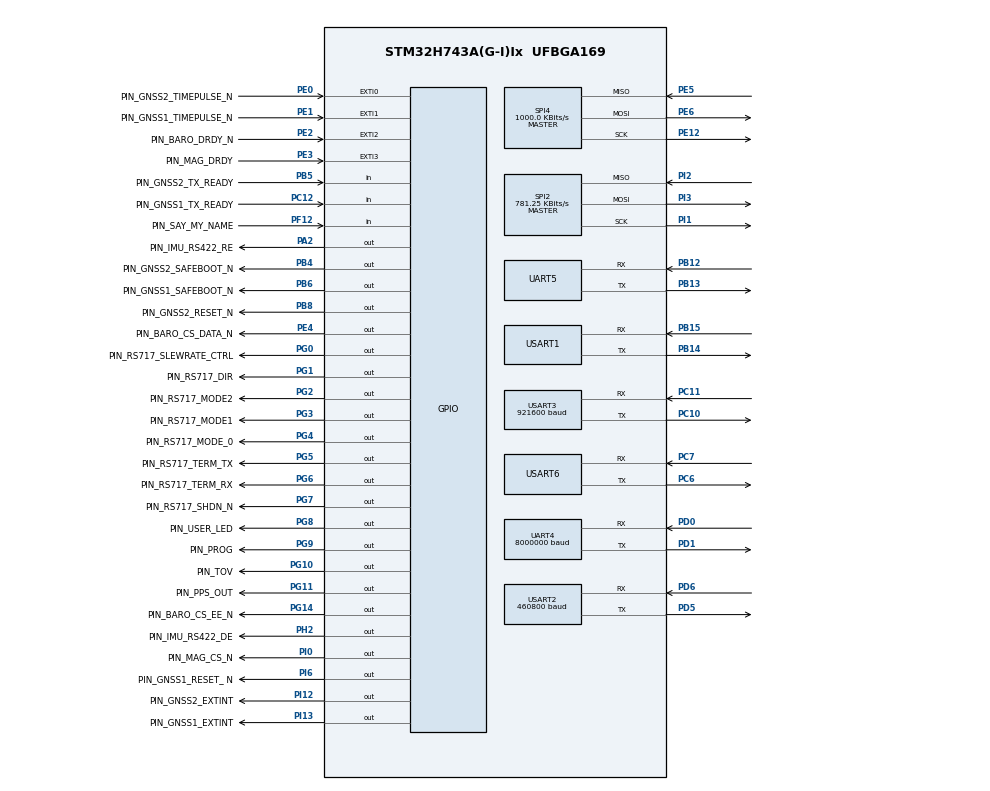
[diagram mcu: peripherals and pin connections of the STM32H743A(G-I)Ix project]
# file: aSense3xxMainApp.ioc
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CORTEX_M7.AccessPermission_Spec=MPU_REGION_FULL_ACCESS
CORTEX_M7.BaseAddress_Spec=0x24078000
CORTEX_M7.CPU_DCache=Enabled
CORTEX_M7.CPU_ICache=Enabled
CORTEX_M7.DisableExec_Spec=MPU_INSTRUCTION_ACCESS_ENABLE
CORTEX_M7.IsBufferable_Spec=MPU_ACCESS_BUFFERABLE
CORTEX_M7.IsShareable_Spec=MPU_ACCESS_SHAREABLE
CORTEX_M7.Size_Spec=MPU_REGION_SIZE_32KB
CORTEX_M7.SubRegionDisable_Spec=0x0
CORTEX_M7.default_mode_Activation=1
Dma.Request0=SPI2_RX
Dma.Request1=SPI2_TX
Dma.Request10=USART1_RX
Dma.Request11=USART1_TX
Dma.Request12=UART5_RX
Dma.Request13=UART5_TX
Dma.Request14=USART6_RX
Dma.Request15=USART6_TX
Dma.Request2=SPI4_RX
Dma.Request3=SPI4_TX
Dma.Request4=UART4_RX
Dma.Request5=UART4_TX
Dma.Request6=USART2_TX
Dma.Request7=USART2_RX
Dma.Request8=USART3_RX
Dma.Request9=USART3_TX
Dma.SPI2_RX.0.Direction=DMA_PERIPH_TO_MEMORY
Dma.SPI2_RX.0.EventEnable=DISABLE
Dma.SPI2_RX.0.FIFOMode=DMA_FIFOMODE_DISABLE
Dma.SPI2_RX.0.Instance=DMA1_Stream0
Dma.SPI2_RX.0.MemDataAlignment=DMA_MDATAALIGN_BYTE
Dma.SPI2_RX.0.MemInc=DMA_MINC_ENABLE
Dma.SPI2_RX.0.Mode=DMA_NORMAL
Dma.SPI2_RX.0.PeriphDataAlignment=DMA_PDATAALIGN_BYTE
Dma.SPI2_RX.0.PeriphInc=DMA_PINC_DISABLE
Dma.SPI2_RX.0.Polarity=HAL_DMAMUX_REQ_GEN_RISING
Dma.SPI2_RX.0.Priority=DMA_PRIORITY_LOW
Dma.SPI2_RX.0.RequestNumber=1
Dma.SPI2_RX.0.SignalID=NONE
Dma.SPI2_RX.0.SyncEnable=DISABLE
Dma.SPI2_RX.0.SyncPolarity=HAL_DMAMUX_SYNC_NO_EVENT
Dma.SPI2_RX.0.SyncRequestNumber=1
Dma.SPI2_RX.0.SyncSignalID=NONE
Dma.SPI2_TX.1.Direction=DMA_MEMORY_TO_PERIPH
Dma.SPI2_TX.1.EventEnable=DISABLE
Dma.SPI2_TX.1.FIFOMode=DMA_FIFOMODE_DISABLE
Dma.SPI2_TX.1.Instance=DMA1_Stream1
Dma.SPI2_TX.1.MemDataAlignment=DMA_MDATAALIGN_BYTE
Dma.SPI2_TX.1.MemInc=DMA_MINC_ENABLE
Dma.SPI2_TX.1.Mode=DMA_NORMAL
Dma.SPI2_TX.1.PeriphDataAlignment=DMA_PDATAALIGN_BYTE
Dma.SPI2_TX.1.PeriphInc=DMA_PINC_DISABLE
Dma.SPI2_TX.1.Polarity=HAL_DMAMUX_REQ_GEN_RISING
Dma.SPI2_TX.1.Priority=DMA_PRIORITY_LOW
Dma.SPI2_TX.1.RequestNumber=1
Dma.SPI2_TX.1.SignalID=NONE
Dma.SPI2_TX.1.SyncEnable=DISABLE
Dma.SPI2_TX.1.SyncPolarity=HAL_DMAMUX_SYNC_NO_EVENT
Dma.SPI2_TX.1.SyncRequestNumber=1
Dma.SPI2_TX.1.SyncSignalID=NONE
Dma.SPI4_RX.2.Direction=DMA_PERIPH_TO_MEMORY
Dma.SPI4_RX.2.EventEnable=DISABLE
Dma.SPI4_RX.2.FIFOMode=DMA_FIFOMODE_DISABLE
Dma.SPI4_RX.2.Instance=DMA1_Stream2
Dma.SPI4_RX.2.MemDataAlignment=DMA_MDATAALIGN_BYTE
Dma.SPI4_RX.2.MemInc=DMA_MINC_ENABLE
Dma.SPI4_RX.2.Mode=DMA_NORMAL
Dma.SPI4_RX.2.PeriphDataAlignment=DMA_PDATAALIGN_BYTE
Dma.SPI4_RX.2.PeriphInc=DMA_PINC_DISABLE
Dma.SPI4_RX.2.Polarity=HAL_DMAMUX_REQ_GEN_RISING
Dma.SPI4_RX.2.Priority=DMA_PRIORITY_LOW
Dma.SPI4_RX.2.RequestNumber=1
Dma.SPI4_RX.2.SignalID=NONE
Dma.SPI4_RX.2.SyncEnable=DISABLE
Dma.SPI4_RX.2.SyncPolarity=HAL_DMAMUX_SYNC_NO_EVENT
Dma.SPI4_RX.2.SyncRequestNumber=1
Dma.SPI4_RX.2.SyncSignalID=NONE
Dma.SPI4_TX.3.Direction=DMA_MEMORY_TO_PERIPH
Dma.SPI4_TX.3.EventEnable=DISABLE
Dma.SPI4_TX.3.FIFOMode=DMA_FIFOMODE_DISABLE
Dma.SPI4_TX.3.Instance=DMA1_Stream3
Dma.SPI4_TX.3.MemDataAlignment=DMA_MDATAALIGN_BYTE
Dma.SPI4_TX.3.MemInc=DMA_MINC_ENABLE
Dma.SPI4_TX.3.Mode=DMA_NORMAL
Dma.SPI4_TX.3.PeriphDataAlignment=DMA_PDATAALIGN_BYTE
Dma.SPI4_TX.3.PeriphInc=DMA_PINC_DISABLE
Dma.SPI4_TX.3.Polarity=HAL_DMAMUX_REQ_GEN_RISING
Dma.SPI4_TX.3.Priority=DMA_PRIORITY_LOW
Dma.SPI4_TX.3.RequestNumber=1
Dma.SPI4_TX.3.SignalID=NONE
Dma.SPI4_TX.3.SyncEnable=DISABLE
Dma.SPI4_TX.3.SyncPolarity=HAL_DMAMUX_SYNC_NO_EVENT
Dma.SPI4_TX.3.SyncRequestNumber=1
Dma.SPI4_TX.3.SyncSignalID=NONE
Dma.UART4_RX.4.Direction=DMA_PERIPH_TO_MEMORY
Dma.UART4_RX.4.EventEnable=DISABLE
Dma.UART4_RX.4.FIFOMode=DMA_FIFOMODE_DISABLE
Dma.UART4_RX.4.Instance=DMA1_Stream4
Dma.UART4_RX.4.MemDataAlignment=DMA_MDATAALIGN_BYTE
Dma.UART4_RX.4.MemInc=DMA_MINC_ENABLE
Dma.UART4_RX.4.Mode=DMA_CIRCULAR
Dma.UART4_RX.4.PeriphDataAlignment=DMA_PDATAALIGN_BYTE
Dma.UART4_RX.4.PeriphInc=DMA_PINC_DISABLE
Dma.UART4_RX.4.Polarity=HAL_DMAMUX_REQ_GEN_RISING
Dma.UART4_RX.4.Priority=DMA_PRIORITY_LOW
Dma.UART4_RX.4.RequestNumber=1
Dma.UART4_RX.4.SignalID=NONE
Dma.UART4_RX.4.SyncEnable=DISABLE
Dma.UART4_RX.4.SyncPolarity=HAL_DMAMUX_SYNC_NO_EVENT
Dma.UART4_RX.4.SyncRequestNumber=1
Dma.UART4_RX.4.SyncSignalID=NONE
Dma.UART4_TX.5.Direction=DMA_MEMORY_TO_PERIPH
Dma.UART4_TX.5.EventEnable=DISABLE
Dma.UART4_TX.5.FIFOMode=DMA_FIFOMODE_DISABLE
Dma.UART4_TX.5.Instance=DMA1_Stream5
Dma.UART4_TX.5.MemDataAlignment=DMA_MDATAALIGN_BYTE
Dma.UART4_TX.5.MemInc=DMA_MINC_ENABLE
Dma.UART4_TX.5.Mode=DMA_NORMAL
Dma.UART4_TX.5.PeriphDataAlignment=DMA_PDATAALIGN_BYTE
Dma.UART4_TX.5.PeriphInc=DMA_PINC_DISABLE
Dma.UART4_TX.5.Polarity=HAL_DMAMUX_REQ_GEN_RISING
Dma.UART4_TX.5.Priority=DMA_PRIORITY_LOW
Dma.UART4_TX.5.RequestNumber=1
Dma.UART4_TX.5.SignalID=NONE
Dma.UART4_TX.5.SyncEnable=DISABLE
Dma.UART4_TX.5.SyncPolarity=HAL_DMAMUX_SYNC_NO_EVENT
Dma.UART4_TX.5.SyncRequestNumber=1
Dma.UART4_TX.5.SyncSignalID=NONE
Dma.UART5_RX.12.Direction=DMA_PERIPH_TO_MEMORY
Dma.UART5_RX.12.EventEnable=DISABLE
Dma.UART5_RX.12.FIFOMode=DMA_FIFOMODE_DISABLE
Dma.UART5_RX.12.Instance=DMA2_Stream0
Dma.UART5_RX.12.MemDataAlignment=DMA_MDATAALIGN_BYTE
Dma.UART5_RX.12.MemInc=DMA_MINC_ENABLE
Dma.UART5_RX.12.Mode=DMA_CIRCULAR
Dma.UART5_RX.12.PeriphDataAlignment=DMA_PDATAALIGN_BYTE
Dma.UART5_RX.12.PeriphInc=DMA_PINC_DISABLE
Dma.UART5_RX.12.Polarity=HAL_DMAMUX_REQ_GEN_RISING
Dma.UART5_RX.12.Priority=DMA_PRIORITY_LOW
Dma.UART5_RX.12.RequestNumber=1
Dma.UART5_RX.12.SignalID=NONE
Dma.UART5_RX.12.SyncEnable=DISABLE
Dma.UART5_RX.12.SyncPolarity=HAL_DMAMUX_SYNC_NO_EVENT
Dma.UART5_RX.12.SyncRequestNumber=1
Dma.UART5_RX.12.SyncSignalID=NONE
Dma.UART5_TX.13.Direction=DMA_MEMORY_TO_PERIPH
Dma.UART5_TX.13.EventEnable=DISABLE
Dma.UART5_TX.13.FIFOMode=DMA_FIFOMODE_DISABLE
Dma.UART5_TX.13.Instance=DMA2_Stream1
Dma.UART5_TX.13.MemDataAlignment=DMA_MDATAALIGN_BYTE
Dma.UART5_TX.13.MemInc=DMA_MINC_ENABLE
Dma.UART5_TX.13.Mode=DMA_NORMAL
Dma.UART5_TX.13.PeriphDataAlignment=DMA_PDATAALIGN_BYTE
Dma.UART5_TX.13.PeriphInc=DMA_PINC_DISABLE
Dma.UART5_TX.13.Polarity=HAL_DMAMUX_REQ_GEN_RISING
Dma.UART5_TX.13.Priority=DMA_PRIORITY_LOW
Dma.UART5_TX.13.RequestNumber=1
Dma.UART5_TX.13.SignalID=NONE
Dma.UART5_TX.13.SyncEnable=DISABLE
Dma.UART5_TX.13.SyncPolarity=HAL_DMAMUX_SYNC_NO_EVENT
Dma.UART5_TX.13.SyncRequestNumber=1
Dma.UART5_TX.13.SyncSignalID=NONE
Dma.USART1_RX.10.Direction=DMA_PERIPH_TO_MEMORY
Dma.USART1_RX.10.EventEnable=DISABLE
Dma.USART1_RX.10.FIFOMode=DMA_FIFOMODE_DISABLE
Dma.USART1_RX.10.Instance=DMA1_Stream6
Dma.USART1_RX.10.MemDataAlignment=DMA_MDATAALIGN_BYTE
Dma.USART1_RX.10.MemInc=DMA_MINC_ENABLE
Dma.USART1_RX.10.Mode=DMA_CIRCULAR
Dma.USART1_RX.10.PeriphDataAlignment=DMA_PDATAALIGN_BYTE
Dma.USART1_RX.10.PeriphInc=DMA_PINC_DISABLE
Dma.USART1_RX.10.Polarity=HAL_DMAMUX_REQ_GEN_RISING
Dma.USART1_RX.10.Priority=DMA_PRIORITY_LOW
Dma.USART1_RX.10.RequestNumber=1
Dma.USART1_RX.10.SignalID=NONE
Dma.USART1_RX.10.SyncEnable=DISABLE
Dma.USART1_RX.10.SyncPolarity=HAL_DMAMUX_SYNC_NO_EVENT
Dma.USART1_RX.10.SyncRequestNumber=1
Dma.USART1_RX.10.SyncSignalID=NONE
Dma.USART1_TX.11.Direction=DMA_MEMORY_TO_PERIPH
Dma.USART1_TX.11.EventEnable=DISABLE
Dma.USART1_TX.11.FIFOMode=DMA_FIFOMODE_DISABLE
Dma.USART1_TX.11.Instance=DMA1_Stream7
Dma.USART1_TX.11.MemDataAlignment=DMA_MDATAALIGN_BYTE
Dma.USART1_TX.11.MemInc=DMA_MINC_ENABLE
Dma.USART1_TX.11.Mode=DMA_NORMAL
Dma.USART1_TX.11.PeriphDataAlignment=DMA_PDATAALIGN_BYTE
Dma.USART1_TX.11.PeriphInc=DMA_PINC_DISABLE
Dma.USART1_TX.11.Polarity=HAL_DMAMUX_REQ_GEN_RISING
Dma.USART1_TX.11.Priority=DMA_PRIORITY_LOW
Dma.USART1_TX.11.RequestNumber=1
Dma.USART1_TX.11.SignalID=NONE
Dma.USART1_TX.11.SyncEnable=DISABLE
Dma.USART1_TX.11.SyncPolarity=HAL_DMAMUX_SYNC_NO_EVENT
Dma.USART1_TX.11.SyncRequestNumber=1
Dma.USART1_TX.11.SyncSignalID=NONE
Dma.USART2_RX.7.Direction=DMA_PERIPH_TO_MEMORY
Dma.USART2_RX.7.EventEnable=DISABLE
Dma.USART2_RX.7.FIFOMode=DMA_FIFOMODE_DISABLE
Dma.USART2_RX.7.Instance=DMA2_Stream3
Dma.USART2_RX.7.MemDataAlignment=DMA_MDATAALIGN_BYTE
Dma.USART2_RX.7.MemInc=DMA_MINC_ENABLE
Dma.USART2_RX.7.Mode=DMA_CIRCULAR
Dma.USART2_RX.7.PeriphDataAlignment=DMA_PDATAALIGN_BYTE
Dma.USART2_RX.7.PeriphInc=DMA_PINC_DISABLE
Dma.USART2_RX.7.Polarity=HAL_DMAMUX_REQ_GEN_RISING
Dma.USART2_RX.7.Priority=DMA_PRIORITY_LOW
Dma.USART2_RX.7.RequestNumber=1
Dma.USART2_RX.7.SignalID=NONE
Dma.USART2_RX.7.SyncEnable=DISABLE
Dma.USART2_RX.7.SyncPolarity=HAL_DMAMUX_SYNC_NO_EVENT
Dma.USART2_RX.7.SyncRequestNumber=1
Dma.USART2_RX.7.SyncSignalID=NONE
Dma.USART2_TX.6.Direction=DMA_MEMORY_TO_PERIPH
Dma.USART2_TX.6.EventEnable=DISABLE
Dma.USART2_TX.6.FIFOMode=DMA_FIFOMODE_DISABLE
Dma.USART2_TX.6.Instance=DMA2_Stream2
Dma.USART2_TX.6.MemDataAlignment=DMA_MDATAALIGN_BYTE
Dma.USART2_TX.6.MemInc=DMA_MINC_ENABLE
Dma.USART2_TX.6.Mode=DMA_NORMAL
Dma.USART2_TX.6.PeriphDataAlignment=DMA_PDATAALIGN_BYTE
Dma.USART2_TX.6.PeriphInc=DMA_PINC_DISABLE
Dma.USART2_TX.6.Polarity=HAL_DMAMUX_REQ_GEN_RISING
Dma.USART2_TX.6.Priority=DMA_PRIORITY_LOW
Dma.USART2_TX.6.RequestNumber=1
Dma.USART2_TX.6.SignalID=NONE
Dma.USART2_TX.6.SyncEnable=DISABLE
Dma.USART2_TX.6.SyncPolarity=HAL_DMAMUX_SYNC_NO_EVENT
Dma.USART2_TX.6.SyncRequestNumber=1
Dma.USART2_TX.6.SyncSignalID=NONE
Dma.USART3_RX.8.Direction=DMA_PERIPH_TO_MEMORY
Dma.USART3_RX.8.EventEnable=DISABLE
Dma.USART3_RX.8.FIFOMode=DMA_FIFOMODE_DISABLE
Dma.USART3_RX.8.Instance=DMA2_Stream4
Dma.USART3_RX.8.MemDataAlignment=DMA_MDATAALIGN_BYTE
Dma.USART3_RX.8.MemInc=DMA_MINC_ENABLE
Dma.USART3_RX.8.Mode=DMA_CIRCULAR
Dma.USART3_RX.8.PeriphDataAlignment=DMA_PDATAALIGN_BYTE
Dma.USART3_RX.8.PeriphInc=DMA_PINC_DISABLE
Dma.USART3_RX.8.Polarity=HAL_DMAMUX_REQ_GEN_RISING
Dma.USART3_RX.8.Priority=DMA_PRIORITY_LOW
Dma.USART3_RX.8.RequestNumber=1
Dma.USART3_RX.8.SignalID=NONE
Dma.USART3_RX.8.SyncEnable=DISABLE
Dma.USART3_RX.8.SyncPolarity=HAL_DMAMUX_SYNC_NO_EVENT
Dma.USART3_RX.8.SyncRequestNumber=1
Dma.USART3_RX.8.SyncSignalID=NONE
Dma.USART3_TX.9.Direction=DMA_MEMORY_TO_PERIPH
Dma.USART3_TX.9.EventEnable=DISABLE
Dma.USART3_TX.9.FIFOMode=DMA_FIFOMODE_DISABLE
Dma.USART3_TX.9.Instance=DMA2_Stream5
Dma.USART3_TX.9.MemDataAlignment=DMA_MDATAALIGN_BYTE
Dma.USART3_TX.9.MemInc=DMA_MINC_ENABLE
Dma.USART3_TX.9.Mode=DMA_NORMAL
Dma.USART3_TX.9.PeriphDataAlignment=DMA_PDATAALIGN_BYTE
Dma.USART3_TX.9.PeriphInc=DMA_PINC_DISABLE
Dma.USART3_TX.9.Polarity=HAL_DMAMUX_REQ_GEN_RISING
Dma.USART3_TX.9.Priority=DMA_PRIORITY_LOW
Dma.USART3_TX.9.RequestNumber=1
Dma.USART3_TX.9.SignalID=NONE
Dma.USART3_TX.9.SyncEnable=DISABLE
Dma.USART3_TX.9.SyncPolarity=HAL_DMAMUX_SYNC_NO_EVENT
Dma.USART3_TX.9.SyncRequestNumber=1
Dma.USART3_TX.9.SyncSignalID=NONE
Dma.USART6_RX.14.Direction=DMA_PERIPH_TO_MEMORY
Dma.USART6_RX.14.EventEnable=DISABLE
Dma.USART6_RX.14.FIFOMode=DMA_FIFOMODE_DISABLE
Dma.USART6_RX.14.Instance=DMA2_Stream6
Dma.USART6_RX.14.MemDataAlignment=DMA_MDATAALIGN_BYTE
Dma.USART6_RX.14.MemInc=DMA_MINC_ENABLE
Dma.USART6_RX.14.Mode=DMA_CIRCULAR
Dma.USART6_RX.14.PeriphDataAlignment=DMA_PDATAALIGN_BYTE
Dma.USART6_RX.14.PeriphInc=DMA_PINC_DISABLE
Dma.USART6_RX.14.Polarity=HAL_DMAMUX_REQ_GEN_RISING
Dma.USART6_RX.14.Priority=DMA_PRIORITY_LOW
Dma.USART6_RX.14.RequestNumber=1
Dma.USART6_RX.14.SignalID=NONE
Dma.USART6_RX.14.SyncEnable=DISABLE
Dma.USART6_RX.14.SyncPolarity=HAL_DMAMUX_SYNC_NO_EVENT
Dma.USART6_RX.14.SyncRequestNumber=1
Dma.USART6_RX.14.SyncSignalID=NONE
Dma.USART6_TX.15.Direction=DMA_MEMORY_TO_PERIPH
Dma.USART6_TX.15.EventEnable=DISABLE
Dma.USART6_TX.15.FIFOMode=DMA_FIFOMODE_DISABLE
Dma.USART6_TX.15.Instance=DMA2_Stream7
Dma.USART6_TX.15.MemDataAlignment=DMA_MDATAALIGN_BYTE
Dma.USART6_TX.15.MemInc=DMA_MINC_ENABLE
Dma.USART6_TX.15.Mode=DMA_NORMAL
Dma.USART6_TX.15.PeriphDataAlignment=DMA_PDATAALIGN_BYTE
Dma.USART6_TX.15.PeriphInc=DMA_PINC_DISABLE
Dma.USART6_TX.15.Polarity=HAL_DMAMUX_REQ_GEN_RISING
Dma.USART6_TX.15.Priority=DMA_PRIORITY_LOW
Dma.USART6_TX.15.RequestNumber=1
Dma.USART6_TX.15.SignalID=NONE
Dma.USART6_TX.15.SyncEnable=DISABLE
Dma.USART6_TX.15.SyncPolarity=HAL_DMAMUX_SYNC_NO_EVENT
Dma.USART6_TX.15.SyncRequestNumber=1
Dma.USART6_TX.15.SyncSignalID=NONE
Mcu.Family=STM32H7
Mcu.Name=STM32H743A(G-I)Ix
Mcu.Package=UFBGA169
Mcu.UserConstants=SPI_BARO,$$_SPI4_IP_HANDLE_$$;UART_DELTAIMU,$$_USART2_IP_HANDLE_$$;SPI_MAGNETO,$$_SPI2_IP_HANDLE_$$;UART_EXTERNAL,$$_UART4_IP_HANDLE_$$;UART_RS717,$$_USART3_IP_HANDLE_$$;UART_GNSS1,$$_USART1_IP_HANDLE_$$;UART_GNSS2,$$_UART5_IP_HANDLE_$$
NVIC.DMA1_Stream0_IRQn=true\:4\:0\:true\:false\:true\:false\:false\:true\:true
NVIC.DMA1_Stream1_IRQn=true\:4\:0\:true\:false\:true\:false\:false\:true\:true
NVIC.DMA1_Stream2_IRQn=true\:4\:0\:true\:false\:true\:false\:false\:true\:true
NVIC.DMA1_Stream3_IRQn=true\:4\:0\:true\:false\:true\:false\:false\:true\:true
NVIC.DMA1_Stream4_IRQn=true\:4\:0\:true\:false\:true\:false\:false\:true\:true
NVIC.DMA1_Stream5_IRQn=true\:4\:0\:true\:false\:true\:false\:false\:true\:true
NVIC.DMA1_Stream6_IRQn=true\:4\:0\:true\:false\:true\:true\:false\:true\:true
NVIC.DMA1_Stream7_IRQn=true\:4\:0\:true\:false\:true\:true\:false\:true\:true
NVIC.DMA2_Stream0_IRQn=true\:4\:0\:true\:false\:true\:true\:false\:true\:true
NVIC.DMA2_Stream1_IRQn=true\:4\:0\:true\:false\:true\:true\:false\:true\:true
NVIC.DMA2_Stream2_IRQn=true\:4\:0\:true\:false\:true\:false\:false\:true\:true
NVIC.DMA2_Stream3_IRQn=true\:4\:0\:true\:false\:true\:false\:false\:true\:true
NVIC.DMA2_Stream4_IRQn=true\:4\:0\:true\:false\:true\:false\:false\:true\:true
NVIC.DMA2_Stream5_IRQn=true\:4\:0\:true\:false\:true\:false\:false\:true\:true
NVIC.DMA2_Stream6_IRQn=true\:4\:0\:true\:false\:true\:true\:false\:true\:true
NVIC.DMA2_Stream7_IRQn=true\:4\:0\:true\:false\:true\:true\:false\:true\:true
NVIC.EXTI0_IRQn=true\:2\:0\:true\:false\:true\:false\:true\:true\:true
NVIC.EXTI1_IRQn=true\:0\:0\:true\:false\:true\:false\:true\:true\:true
NVIC.EXTI2_IRQn=true\:4\:0\:true\:false\:true\:false\:true\:true\:true
NVIC.EXTI3_IRQn=true\:4\:0\:true\:false\:true\:false\:true\:true\:true
NVIC.PriorityGroup=NVIC_PRIORITYGROUP_4
NVIC.SPI2_IRQn=true\:4\:0\:true\:false\:true\:false\:false\:true\:true
NVIC.SPI4_IRQn=true\:4\:0\:true\:false\:true\:false\:false\:true\:true
NVIC.TIM2_IRQn=true\:1\:0\:true\:false\:true\:false\:true\:true\:true
NVIC.TIM3_IRQn=true\:4\:0\:true\:false\:true\:false\:true\:true\:true
NVIC.TIM6_DAC_IRQn=true\:15\:0\:false\:false\:true\:false\:false\:true\:true
NVIC.TimeBase=TIM6_DAC_IRQn
NVIC.TimeBaseIP=TIM6
NVIC.UART4_IRQn=true\:4\:0\:true\:false\:true\:false\:true\:true\:true
NVIC.UART5_IRQn=true\:4\:0\:true\:false\:true\:false\:true\:true\:true
NVIC.USART1_IRQn=true\:4\:0\:true\:false\:true\:false\:true\:true\:true
NVIC.USART2_IRQn=true\:4\:0\:true\:false\:true\:false\:true\:true\:true
NVIC.USART3_IRQn=true\:4\:0\:true\:false\:true\:false\:true\:true\:true
NVIC.USART6_IRQn=true\:4\:0\:true\:false\:true\:false\:true\:true\:true
PA13\ (JTMS/SWDIO).Mode=Serial_Wire
PA13\ (JTMS/SWDIO).Signal=DEBUG_JTMS-SWDIO
PA14\ (JTCK/SWCLK).Mode=Serial_Wire
PA14\ (JTCK/SWCLK).Signal=DEBUG_JTCK-SWCLK
PA2.GPIO_Label=PIN_IMU_RS422_RE
PA2.GPIO_PuPd=GPIO_PULLDOWN
PA2.PinAttribute=Free
PA2.Signal=GPIO_Output
PB12.GPIO_PuPd=GPIO_PULLUP
PB12.Mode=Asynchronous
PB12.Signal=UART5_RX
PB13.GPIO_PuPd=GPIO_PULLUP
PB13.Mode=Asynchronous
PB13.PinAttribute=Free
PB13.Signal=UART5_TX
PB14.GPIO_PuPd=GPIO_PULLUP
PB14.Mode=Asynchronous
PB14.Signal=USART1_TX
PB15.GPIO_PuPd=GPIO_PULLUP
PB15.Mode=Asynchronous
PB15.PinAttribute=Free
PB15.Signal=USART1_RX
PB4\ (NJTRST).GPIO_Label=PIN_GNSS2_SAFEBOOT_N
PB4\ (NJTRST).PinAttribute=Free
PB4\ (NJTRST).PinState=GPIO_PIN_SET
PB4\ (NJTRST).Signal=GPIO_Output
PB5.GPIO_Label=PIN_GNSS2_TX_READY
PB5.Signal=GPIO_Input
PB6.GPIO_Label=PIN_GNSS1_SAFEBOOT_N
PB6.PinState=GPIO_PIN_SET
PB6.Signal=GPIO_Output
PB8.GPIO_Label=PIN_GNSS2_RESET_N
PB8.PinAttribute=Free
PB8.PinState=GPIO_PIN_SET
PB8.Signal=GPIO_Output
PC10.GPIO_PuPd=GPIO_PULLUP
PC10.Mode=Asynchronous
PC10.Signal=USART3_TX
PC11.GPIO_PuPd=GPIO_PULLUP
PC11.Mode=Asynchronous
PC11.Signal=USART3_RX
PC12.GPIO_Label=PIN_GNSS1_TX_READY
PC12.Signal=GPIO_Input
PC14-OSC32_IN\ (OSC32_IN).Mode=LSE-External-Oscillator
PC14-OSC32_IN\ (OSC32_IN).Signal=RCC_OSC32_IN
PC15-OSC32_OUT\ (OSC32_OUT).Mode=LSE-External-Oscillator
PC15-OSC32_OUT\ (OSC32_OUT).Signal=RCC_OSC32_OUT
PC6.GPIO_PuPd=GPIO_PULLUP
PC6.Mode=Asynchronous
PC6.PinAttribute=Free
PC6.Signal=USART6_TX
PC7.GPIO_PuPd=GPIO_PULLUP
PC7.Mode=Asynchronous
PC7.PinAttribute=Free
PC7.Signal=USART6_RX
PD0.GPIO_PuPd=GPIO_PULLUP
PD0.GPIO_Speed=GPIO_SPEED_FREQ_VERY_HIGH
PD0.Mode=Asynchronous
PD0.Signal=UART4_RX
PD1.GPIO_PuPd=GPIO_PULLUP
PD1.GPIO_Speed=GPIO_SPEED_FREQ_VERY_HIGH
PD1.Mode=Asynchronous
PD1.Signal=UART4_TX
PD5.GPIO_PuPd=GPIO_PULLUP
PD5.Mode=Asynchronous
PD5.Signal=USART2_TX
PD6.GPIO_PuPd=GPIO_PULLUP
PD6.Mode=Asynchronous
PD6.Signal=USART2_RX
PE0.GPIO_Label=PIN_GNSS2_TIMEPULSE_N
PE0.GPIO_ModeDefaultEXTI=GPIO_MODE_IT_FALLING
PE0.Signal=GPXTI0
PE1.GPIO_Label=PIN_GNSS1_TIMEPULSE_N
PE1.GPIO_ModeDefaultEXTI=GPIO_MODE_IT_RISING_FALLING
PE1.Signal=GPXTI1
PE12.GPIO_Speed=GPIO_SPEED_FREQ_HIGH
PE12.Mode=Full_Duplex_Master
PE12.PinAttribute=Free
PE12.Signal=SPI4_SCK
PE2.GPIO_Label=PIN_BARO_DRDY_N
PE2.GPIO_ModeDefaultEXTI=GPIO_MODE_IT_FALLING
PE2.Signal=GPXTI2
PE3.GPIO_Label=PIN_MAG_DRDY
PE3.GPIO_ModeDefaultEXTI=GPIO_MODE_IT_RISING
PE3.Signal=GPXTI3
PE4.GPIO_Label=PIN_BARO_CS_DATA_N
PE4.GPIO_PuPd=GPIO_PULLUP
PE4.PinState=GPIO_PIN_SET
PE4.Signal=GPIO_Output
PE5.GPIO_Speed=GPIO_SPEED_FREQ_HIGH
PE5.Mode=Full_Duplex_Master
PE5.Signal=SPI4_MISO
PE6.GPIO_Speed=GPIO_SPEED_FREQ_HIGH
PE6.Mode=Full_Duplex_Master
PE6.Signal=SPI4_MOSI
PF12.GPIO_Label=PIN_SAY_MY_NAME
PF12.GPIO_PuPd=GPIO_PULLDOWN
PF12.PinAttribute=Free
PF12.Signal=GPIO_Input
PG0.GPIO_Label=PIN_RS717_SLEWRATE_CTRL
PG0.Signal=GPIO_Output
PG1.GPIO_Label=PIN_RS717_DIR
PG1.PinState=GPIO_PIN_RESET
PG1.Signal=GPIO_Output
PG10.GPIO_Label=PIN_TOV
PG10.Signal=GPIO_Output
PG11.GPIO_Label=PIN_PPS_OUT
PG11.GPIO_Speed=GPIO_SPEED_FREQ_LOW
PG11.PinAttribute=Free
PG11.PinState=GPIO_PIN_SET
PG11.Signal=GPIO_Output
PG14.GPIO_Label=PIN_BARO_CS_EE_N
PG14.PinState=GPIO_PIN_SET
PG14.Signal=GPIO_Output
PG2.GPIO_Label=PIN_RS717_MODE2
PG2.PinAttribute=Free
PG2.Signal=GPIO_Output
PG3.GPIO_Label=PIN_RS717_MODE1
PG3.PinAttribute=Free
PG3.Signal=GPIO_Output
PG4.GPIO_Label=PIN_RS717_MODE_0
PG4.PinState=GPIO_PIN_SET
PG4.Signal=GPIO_Output
PG5.GPIO_Label=PIN_RS717_TERM_TX
PG5.PinAttribute=Free
PG5.Signal=GPIO_Output
PG6.GPIO_Label=PIN_RS717_TERM_RX
PG6.PinAttribute=Free
PG6.Signal=GPIO_Output
PG7.GPIO_Label=PIN_RS717_SHDN_N
PG7.PinAttribute=Free
PG7.Signal=GPIO_Output
PG8.GPIO_Label=PIN_USER_LED
PG8.PinAttribute=Free
PG8.PinState=GPIO_PIN_SET
PG8.Signal=GPIO_Output
PG9.GPIO_Label=PIN_PROG
PG9.Signal=GPIO_Output
PH0-OSC_IN\ (PH0).Mode=HSE-External-Oscillator
PH0-OSC_IN\ (PH0).PinAttribute=Free
PH0-OSC_IN\ (PH0).Signal=RCC_OSC_IN
PH1-OSC_OUT\ (PH1).Mode=HSE-External-Oscillator
PH1-OSC_OUT\ (PH1).PinAttribute=Free
PH1-OSC_OUT\ (PH1).Signal=RCC_OSC_OUT
PH2.GPIO_Label=PIN_IMU_RS422_DE
PH2.GPIO_PuPd=GPIO_PULLDOWN
PH2.PinAttribute=Free
PH2.Signal=GPIO_Output
PI0.GPIO_Label=PIN_MAG_CS_N
PI0.PinState=GPIO_PIN_SET
PI0.Signal=GPIO_Output
PI1.Mode=Full_Duplex_Master
PI1.Signal=SPI2_SCK
PI12.GPIO_Label=PIN_GNSS2_EXTINT
PI12.Signal=GPIO_Output
PI13.GPIO_Label=PIN_GNSS1_EXTINT
PI13.Signal=GPIO_Output
PI2.Mode=Full_Duplex_Master
PI2.Signal=SPI2_MISO
PI3.Mode=Full_Duplex_Master
PI3.PinAttribute=Free
PI3.Signal=SPI2_MOSI
PI6.GPIO_Label=PIN_GNSS1_RESET_ N
PI6.PinState=GPIO_PIN_SET
PI6.Signal=GPIO_Output
ProjectManager.HeapSize=0x25000
ProjectManager.StackSize=0x1000
ProjectManager.TargetToolchain=STM32CubeIDE
RCC.ADCFreq_Value=75000000
RCC.APB1Freq_Value=100000000
RCC.APB2Freq_Value=100000000
RCC.APB3Freq_Value=100000000
RCC.APB4Freq_Value=100000000
RCC.CKPERSourceSelection=RCC_CLKPSOURCE_HSE
RCC.CortexFreq_Value=400000000
RCC.D1PPRE=RCC_APB3_DIV2
RCC.D2PPRE1=RCC_APB1_DIV2
RCC.D2PPRE2=RCC_APB2_DIV2
RCC.D3PPRE=RCC_APB4_DIV2
RCC.DIVM1=2
RCC.DIVM2=2
RCC.DIVM3=5
RCC.DIVN1=64
RCC.DIVN2=12
RCC.DIVN3=64
RCC.DIVP3=5
RCC.DIVQ1=4
RCC.DIVQ3=5
RCC.HCLKFreq_Value=200000000
RCC.HPRE=RCC_HCLK_DIV2
RCC.PLL1_VCI_Range-AdvancedSettings=RCC_PLL1VCIRANGE_0
RCC.PLL2FRACN=0
RCC.PLL2_VCI_Range-AdvancedSettings=RCC_PLL2VCIRANGE_0
RCC.PLL3FRACN=0
RCC.PLL3_VCI_Range-AdvancedSettings=RCC_PLL3VCIRANGE_0
RCC.PLLFRACN=0
RCC.PLLSourceVirtual=RCC_PLLSOURCE_HSE
RCC.SYSCLKFreq_VALUE=400000000
RCC.SYSCLKSource=RCC_SYSCLKSOURCE_PLLCLK
RCC.Spi45ClockSelection=RCC_SPI45CLKSOURCE_HSI
RCC.USART234578CLockSelection=RCC_USART234578CLKSOURCE_PLL3
RCC.USBFreq_Value=200000000
SPI2.BaudRatePrescaler=SPI_BAUDRATEPRESCALER_256
SPI2.CalculateBaudRate=781.25 KBits/s
SPI2.DataSize=SPI_DATASIZE_8BIT
SPI2.Direction=SPI_DIRECTION_2LINES
SPI2.Mode=SPI_MODE_MASTER
SPI2.NSSPMode=SPI_NSS_PULSE_DISABLE
SPI2.VirtualType=VM_MASTER
SPI4.BaudRatePrescaler=SPI_BAUDRATEPRESCALER_64
SPI4.CalculateBaudRate=1000.0 KBits/s
SPI4.DataSize=SPI_DATASIZE_8BIT
SPI4.Direction=SPI_DIRECTION_2LINES
SPI4.MasterInterDataIdleness=SPI_MASTER_INTERDATA_IDLENESS_15CYCLE
SPI4.MasterKeepIOState=SPI_MASTER_KEEP_IO_STATE_ENABLE
SPI4.MasterReceiverAutoSusp=SPI_MASTER_RX_AUTOSUSP_DISABLE
SPI4.MasterSSIdleness=SPI_MASTER_SS_IDLENESS_15CYCLE
SPI4.Mode=SPI_MODE_MASTER
SPI4.NSSPMode=SPI_NSS_PULSE_ENABLE
SPI4.VirtualType=VM_MASTER
STMicroelectronics.X-CUBE-ALGOBUILD.1.4.0.LibraryCcDSPOoLibraryJjDSPOoLibrary=true
STMicroelectronics.X-CUBE-AZRTOS-H7.3.3.0.TX_APP_MEM_POOL_SIZE=1024*256
STMicroelectronics.X-CUBE-AZRTOS-H7.3.3.0.TX_BASEPRI_SUPPORT=1
STMicroelectronics.X-CUBE-AZRTOS-H7.3.3.0.TX_BASEPRI_VALUE=1
STMicroelectronics.X-CUBE-AZRTOS-H7.3.3.0.TX_BLOCK_POOL_ENABLE_PERFORMANCE_INFO=1
STMicroelectronics.X-CUBE-AZRTOS-H7.3.3.0.TX_BYTE_POOL_ENABLE_PERFORMANCE_INFO=1
STMicroelectronics.X-CUBE-AZRTOS-H7.3.3.0.TX_ENABLE_STACK_CHECKING=1
STMicroelectronics.X-CUBE-AZRTOS-H7.3.3.0.TX_EVENT_FLAGS_ENABLE_PERFORMANCE_INFO=1
STMicroelectronics.X-CUBE-AZRTOS-H7.3.3.0.TX_INLINE_THREAD_RESUME_SUSPEND=1
STMicroelectronics.X-CUBE-AZRTOS-H7.3.3.0.TX_MAX_PRIORITIES=64
STMicroelectronics.X-CUBE-AZRTOS-H7.3.3.0.TX_MUTEX_ENABLE_PERFORMANCE_INFO=1
STMicroelectronics.X-CUBE-AZRTOS-H7.3.3.0.TX_QUEUE_ENABLE_PERFORMANCE_INFO=1
STMicroelectronics.X-CUBE-AZRTOS-H7.3.3.0.TX_SEMAPHORE_ENABLE_PERFORMANCE_INFO=1
STMicroelectronics.X-CUBE-AZRTOS-H7.3.3.0.TX_THREAD_ENABLE_PERFORMANCE_INFO=1
STMicroelectronics.X-CUBE-AZRTOS-H7.3.3.0.TX_TIMER_ENABLE_PERFORMANCE_INFO=1
STMicroelectronics.X-CUBE-AZRTOS-H7.3.3.0.TX_TIMER_TICKS_PER_SECOND=1000
STMicroelectronics.X-CUBE-AZRTOS-H7.3.3.0.ThreadXCcRTOSJjThreadXJjCore=true
STMicroelectronics.X-CUBE-AZRTOS-H7.3.3.0.ThreadXCcRTOSJjThreadXJjPerformanceInfo=true
STMicroelectronics.X-CUBE-AZRTOS-H7.3.3.0_IsAnAzureRtosMw=true
STMicroelectronics.X-CUBE-MEMS1.12.0.0.SensorsJjSTM32IiMotionMCIiLibraryJjCore=true
TIM2.ClockDivision=TIM_CLOCKDIVISION_DIV4
TIM2.Period=500-1
TIM2.Prescaler=500-1
TIM3.ClockDivision=TIM_CLOCKDIVISION_DIV4
TIM3.Period=400-1
TIM3.Prescaler=500-1
TIM3.TIM_MasterOutputTrigger=TIM_TRGO_RESET
UART4.BaudRate=8000000
UART4.OverSampling=UART_OVERSAMPLING_8
UART4.OverrunDisableParam=UART_ADVFEATURE_OVERRUN_DISABLE
UART5.OverrunDisableParam=UART_ADVFEATURE_OVERRUN_DISABLE
USART1.OverrunDisableParam=ADVFEATURE_OVERRUN_DISABLE
USART1.VirtualMode-Asynchronous=VM_ASYNC
USART2.BaudRate=460800
USART2.OverrunDisableParam=ADVFEATURE_OVERRUN_DISABLE
USART2.VirtualMode-Asynchronous=VM_ASYNC
USART3.BaudRate=921600
USART3.OverrunDisableParam=ADVFEATURE_OVERRUN_DISABLE
USART3.VirtualMode-Asynchronous=VM_ASYNC
USART6.OverrunDisableParam=ADVFEATURE_OVERRUN_DISABLE
USART6.VirtualMode-Asynchronous=VM_ASYNC
VP_CRC_VS_CRC.Mode=CRC_Activate
VP_MEMORYMAP_VS_MEMORYMAP.Mode=CurAppReg
VP_STMicroelectronics.X-CUBE-ALGOBUILD_VS_DSPOoLibraryJjLibrary_1.4.0_1.4.0.Mode=DSPOoLibraryJjLibrary
VP_STMicroelectronics.X-CUBE-AZRTOS-H7_VS_RTOSJjThreadX_6.4.0_3.3.0.Mode=RTOSJjThreadX
VP_STMicroelectronics.X-CUBE-MEMS1_VS_SensorsJjSTM32IiMotionMCIiLibrary_2.8.0_12.0.0.Mode=SensorsJjSTM32IiMotionMCIiLibrary
VP_SYS_VS_tim6.Mode=TIM6
VP_TIM2_VS_ClockSourceINT.Mode=Internal
VP_TIM3_VS_ClockSourceINT.Mode=Internal
board=custom

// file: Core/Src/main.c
/* USER CODE BEGIN Header */
/**
  ******************************************************************************
  * @file           : main.c
  * @brief          : Main program body
  ******************************************************************************
  * @attention
  *
  * Copyright (c) 2025 STMicroelectronics.
  * All rights reserved.
  *
  * This software is licensed under terms that can be found in the LICENSE file
  * in the root directory of this software component.
  * If no LICENSE file comes with this software, it is provided AS-IS.
  *
  ******************************************************************************
  */
/* USER CODE END Header */
#include "app_threadx.h"
#include "main.h"

/* USER CODE BEGIN PTD */
char MotionMC_LoadCalFromNVM(unsigned short int datasize, unsigned int *data){
 return 1; /* FAILURE: Read from NVM not implemented. */
}

char MotionMC_SaveCalInNVM(unsigned short int datasize, unsigned int *data){
 return 1; /* FAILURE: Write to NVM not implemented. */
}
/* USER CODE END PTD */

CRC_HandleTypeDef hcrc;

SPI_HandleTypeDef hspi2;
SPI_HandleTypeDef hspi4;
DMA_HandleTypeDef hdma_spi2_rx;
DMA_HandleTypeDef hdma_spi2_tx;
DMA_HandleTypeDef hdma_spi4_rx;
DMA_HandleTypeDef hdma_spi4_tx;

TIM_HandleTypeDef htim2;
TIM_HandleTypeDef htim3;

UART_HandleTypeDef huart4;
UART_HandleTypeDef huart5;
UART_HandleTypeDef huart1;
UART_HandleTypeDef huart2;
UART_HandleTypeDef huart3;
UART_HandleTypeDef huart6;
DMA_HandleTypeDef hdma_uart4_rx;
DMA_HandleTypeDef hdma_uart4_tx;
DMA_HandleTypeDef hdma_uart5_rx;
DMA_HandleTypeDef hdma_uart5_tx;
DMA_HandleTypeDef hdma_usart1_rx;
DMA_HandleTypeDef hdma_usart1_tx;
DMA_HandleTypeDef hdma_usart2_tx;
DMA_HandleTypeDef hdma_usart2_rx;
DMA_HandleTypeDef hdma_usart3_rx;
DMA_HandleTypeDef hdma_usart3_tx;
DMA_HandleTypeDef hdma_usart6_rx;
DMA_HandleTypeDef hdma_usart6_tx;

/* USER CODE BEGIN PV */
#if !defined(MAX_UART_DEVICE_CNT)
#define MAX_UART_DEVICE_CNT 7
#endif
UART_HandleTypeDef *uart_created_list[MAX_UART_DEVICE_CNT] = {NULL};

#if !defined(MAX_SPI_DEVICE_CNT)
#define MAX_SPI_DEVICE_CNT 6
#endif
SPI_HandleTypeDef *spi_created_list[MAX_SPI_DEVICE_CNT] = {NULL};

/* USER CODE END PV */

void SystemClock_Config(void);
void PeriphCommonClock_Config(void);
static void MPU_Config(void);
static void MX_GPIO_Init(void);
static void MX_DMA_Init(void);
static void MX_UART4_Init(void);
static void MX_USART3_UART_Init(void);
static void MX_SPI2_Init(void);
static void MX_USART2_UART_Init(void);
static void MX_SPI4_Init(void);
static void MX_USART1_UART_Init(void);
static void MX_TIM3_Init(void);
static void MX_UART5_Init(void);
static void MX_CRC_Init(void);
static void MX_TIM2_Init(void);
static void MX_USART6_UART_Init(void);

int main(void)
{

  /* MPU Configuration--------------------------------------------------------*/
  MPU_Config();

  /* Enable the CPU Cache */

  /* Enable I-Cache---------------------------------------------------------*/
  SCB_EnableICache();

  /* Enable D-Cache---------------------------------------------------------*/
  SCB_EnableDCache();

  /* MCU Configuration--------------------------------------------------------*/

  /* Reset of all peripherals, Initializes the Flash interface and the Systick. */
  HAL_Init();

  /* Configure the system clock */
  SystemClock_Config();

  /* Configure the peripherals common clocks */
  PeriphCommonClock_Config();

  /* Initialize all configured peripherals */
  MX_GPIO_Init();
  MX_DMA_Init();
  MX_UART4_Init();
  MX_USART3_UART_Init();
  MX_SPI2_Init();
  MX_USART2_UART_Init();
  MX_SPI4_Init();
  MX_USART1_UART_Init();
  MX_TIM3_Init();
  MX_UART5_Init();
  MX_CRC_Init();
  MX_TIM2_Init();
  MX_USART6_UART_Init();

  MX_ThreadX_Init();

  /* We should never get here as control is now taken by the scheduler */

  /* Infinite loop */
  while (1)
  {

  }
}

void SystemClock_Config(void)
{
  RCC_OscInitTypeDef RCC_OscInitStruct = {0};
  RCC_ClkInitTypeDef RCC_ClkInitStruct = {0};

  /** Supply configuration update enable
  */
  HAL_PWREx_ConfigSupply(PWR_LDO_SUPPLY);

  /** Configure the main internal regulator output voltage
  */
  __HAL_PWR_VOLTAGESCALING_CONFIG(PWR_REGULATOR_VOLTAGE_SCALE1);

  while(!__HAL_PWR_GET_FLAG(PWR_FLAG_VOSRDY)) {}

  /** Initializes the RCC Oscillators according to the specified parameters
  * in the RCC_OscInitTypeDef structure.
  */
  RCC_OscInitStruct.OscillatorType = RCC_OSCILLATORTYPE_HSI|RCC_OSCILLATORTYPE_HSE;
  RCC_OscInitStruct.HSEState = RCC_HSE_ON;
  RCC_OscInitStruct.HSIState = RCC_HSI_DIV1;
  RCC_OscInitStruct.HSICalibrationValue = RCC_HSICALIBRATION_DEFAULT;
  RCC_OscInitStruct.PLL.PLLState = RCC_PLL_ON;
  RCC_OscInitStruct.PLL.PLLSource = RCC_PLLSOURCE_HSE;
  RCC_OscInitStruct.PLL.PLLM = 2;
  RCC_OscInitStruct.PLL.PLLN = 64;
  RCC_OscInitStruct.PLL.PLLP = 2;
  RCC_OscInitStruct.PLL.PLLQ = 4;
  RCC_OscInitStruct.PLL.PLLR = 2;
  RCC_OscInitStruct.PLL.PLLRGE = RCC_PLL1VCIRANGE_3;
  RCC_OscInitStruct.PLL.PLLVCOSEL = RCC_PLL1VCOWIDE;
  RCC_OscInitStruct.PLL.PLLFRACN = 0;
  if (HAL_RCC_OscConfig(&RCC_OscInitStruct) != HAL_OK)
  {
    Error_Handler();
  }

  /** Initializes the CPU, AHB and APB buses clocks
  */
  RCC_ClkInitStruct.ClockType = RCC_CLOCKTYPE_HCLK|RCC_CLOCKTYPE_SYSCLK
                              |RCC_CLOCKTYPE_PCLK1|RCC_CLOCKTYPE_PCLK2
                              |RCC_CLOCKTYPE_D3PCLK1|RCC_CLOCKTYPE_D1PCLK1;
  RCC_ClkInitStruct.SYSCLKSource = RCC_SYSCLKSOURCE_PLLCLK;
  RCC_ClkInitStruct.SYSCLKDivider = RCC_SYSCLK_DIV1;
  RCC_ClkInitStruct.AHBCLKDivider = RCC_HCLK_DIV2;
  RCC_ClkInitStruct.APB3CLKDivider = RCC_APB3_DIV2;
  RCC_ClkInitStruct.APB1CLKDivider = RCC_APB1_DIV2;
  RCC_ClkInitStruct.APB2CLKDivider = RCC_APB2_DIV2;
  RCC_ClkInitStruct.APB4CLKDivider = RCC_APB4_DIV2;

  if (HAL_RCC_ClockConfig(&RCC_ClkInitStruct, FLASH_LATENCY_2) != HAL_OK)
  {
    Error_Handler();
  }
}

void PeriphCommonClock_Config(void)
{
  RCC_PeriphCLKInitTypeDef PeriphClkInitStruct = {0};

  /** Initializes the peripherals clock
  */
  PeriphClkInitStruct.PeriphClockSelection = RCC_PERIPHCLK_UART5|RCC_PERIPHCLK_UART4
                              |RCC_PERIPHCLK_USART2|RCC_PERIPHCLK_USART3;
  PeriphClkInitStruct.PLL3.PLL3M = 5;
  PeriphClkInitStruct.PLL3.PLL3N = 64;
  PeriphClkInitStruct.PLL3.PLL3P = 5;
  PeriphClkInitStruct.PLL3.PLL3Q = 5;
  PeriphClkInitStruct.PLL3.PLL3R = 2;
  PeriphClkInitStruct.PLL3.PLL3RGE = RCC_PLL3VCIRANGE_2;
  PeriphClkInitStruct.PLL3.PLL3VCOSEL = RCC_PLL3VCOWIDE;
  PeriphClkInitStruct.PLL3.PLL3FRACN = 0;
  PeriphClkInitStruct.Usart234578ClockSelection = RCC_USART234578CLKSOURCE_PLL3;
  if (HAL_RCCEx_PeriphCLKConfig(&PeriphClkInitStruct) != HAL_OK)
  {
    Error_Handler();
  }
}

static void MX_CRC_Init(void)
{

  hcrc.Instance = CRC;
  hcrc.Init.DefaultPolynomialUse = DEFAULT_POLYNOMIAL_ENABLE;
  hcrc.Init.DefaultInitValueUse = DEFAULT_INIT_VALUE_ENABLE;
  hcrc.Init.InputDataInversionMode = CRC_INPUTDATA_INVERSION_NONE;
  hcrc.Init.OutputDataInversionMode = CRC_OUTPUTDATA_INVERSION_DISABLE;
  hcrc.InputDataFormat = CRC_INPUTDATA_FORMAT_BYTES;
  if (HAL_CRC_Init(&hcrc) != HAL_OK)
  {
    Error_Handler();
  }

}

static void MX_SPI2_Init(void)
{

  /* SPI2 parameter configuration*/
  hspi2.Instance = SPI2;
  hspi2.Init.Mode = SPI_MODE_MASTER;
  hspi2.Init.Direction = SPI_DIRECTION_2LINES;
  hspi2.Init.DataSize = SPI_DATASIZE_8BIT;
  hspi2.Init.CLKPolarity = SPI_POLARITY_LOW;
  hspi2.Init.CLKPhase = SPI_PHASE_1EDGE;
  hspi2.Init.NSS = SPI_NSS_SOFT;
  hspi2.Init.BaudRatePrescaler = SPI_BAUDRATEPRESCALER_256;
  hspi2.Init.FirstBit = SPI_FIRSTBIT_MSB;
  hspi2.Init.TIMode = SPI_TIMODE_DISABLE;
  hspi2.Init.CRCCalculation = SPI_CRCCALCULATION_DISABLE;
  hspi2.Init.CRCPolynomial = 0x0;
  hspi2.Init.NSSPMode = SPI_NSS_PULSE_DISABLE;
  hspi2.Init.NSSPolarity = SPI_NSS_POLARITY_LOW;
  hspi2.Init.FifoThreshold = SPI_FIFO_THRESHOLD_01DATA;
  hspi2.Init.TxCRCInitializationPattern = SPI_CRC_INITIALIZATION_ALL_ZERO_PATTERN;
  hspi2.Init.RxCRCInitializationPattern = SPI_CRC_INITIALIZATION_ALL_ZERO_PATTERN;
  hspi2.Init.MasterSSIdleness = SPI_MASTER_SS_IDLENESS_00CYCLE;
  hspi2.Init.MasterInterDataIdleness = SPI_MASTER_INTERDATA_IDLENESS_00CYCLE;
  hspi2.Init.MasterReceiverAutoSusp = SPI_MASTER_RX_AUTOSUSP_DISABLE;
  hspi2.Init.MasterKeepIOState = SPI_MASTER_KEEP_IO_STATE_DISABLE;
  hspi2.Init.IOSwap = SPI_IO_SWAP_DISABLE;
  if (HAL_SPI_Init(&hspi2) != HAL_OK)
  {
    Error_Handler();
  }
  /* USER CODE BEGIN SPI2_Init 2 */
  spi_created_list[1] = &hspi2;
  /* USER CODE END SPI2_Init 2 */

}

static void MX_SPI4_Init(void)
{

  /* SPI4 parameter configuration*/
  hspi4.Instance = SPI4;
  hspi4.Init.Mode = SPI_MODE_MASTER;
  hspi4.Init.Direction = SPI_DIRECTION_2LINES;
  hspi4.Init.DataSize = SPI_DATASIZE_8BIT;
  hspi4.Init.CLKPolarity = SPI_POLARITY_LOW;
  hspi4.Init.CLKPhase = SPI_PHASE_1EDGE;
  hspi4.Init.NSS = SPI_NSS_SOFT;
  hspi4.Init.BaudRatePrescaler = SPI_BAUDRATEPRESCALER_64;
  hspi4.Init.FirstBit = SPI_FIRSTBIT_MSB;
  hspi4.Init.TIMode = SPI_TIMODE_DISABLE;
  hspi4.Init.CRCCalculation = SPI_CRCCALCULATION_DISABLE;
  hspi4.Init.CRCPolynomial = 0x0;
  hspi4.Init.NSSPMode = SPI_NSS_PULSE_ENABLE;
  hspi4.Init.NSSPolarity = SPI_NSS_POLARITY_LOW;
  hspi4.Init.FifoThreshold = SPI_FIFO_THRESHOLD_01DATA;
  hspi4.Init.TxCRCInitializationPattern = SPI_CRC_INITIALIZATION_ALL_ZERO_PATTERN;
  hspi4.Init.RxCRCInitializationPattern = SPI_CRC_INITIALIZATION_ALL_ZERO_PATTERN;
  hspi4.Init.MasterSSIdleness = SPI_MASTER_SS_IDLENESS_15CYCLE;
  hspi4.Init.MasterInterDataIdleness = SPI_MASTER_INTERDATA_IDLENESS_15CYCLE;
  hspi4.Init.MasterReceiverAutoSusp = SPI_MASTER_RX_AUTOSUSP_DISABLE;
  hspi4.Init.MasterKeepIOState = SPI_MASTER_KEEP_IO_STATE_ENABLE;
  hspi4.Init.IOSwap = SPI_IO_SWAP_DISABLE;
  if (HAL_SPI_Init(&hspi4) != HAL_OK)
  {
    Error_Handler();
  }
  /* USER CODE BEGIN SPI4_Init 2 */
  spi_created_list[3] = &hspi4;
  /* USER CODE END SPI4_Init 2 */

}

static void MX_TIM2_Init(void)
{

  TIM_ClockConfigTypeDef sClockSourceConfig = {0};
  TIM_MasterConfigTypeDef sMasterConfig = {0};

  htim2.Instance = TIM2;
  htim2.Init.Prescaler = 500-1;
  htim2.Init.CounterMode = TIM_COUNTERMODE_UP;
  htim2.Init.Period = 500-1;
  htim2.Init.ClockDivision = TIM_CLOCKDIVISION_DIV4;
  htim2.Init.AutoReloadPreload = TIM_AUTORELOAD_PRELOAD_DISABLE;
  if (HAL_TIM_Base_Init(&htim2) != HAL_OK)
  {
    Error_Handler();
  }
  sClockSourceConfig.ClockSource = TIM_CLOCKSOURCE_INTERNAL;
  if (HAL_TIM_ConfigClockSource(&htim2, &sClockSourceConfig) != HAL_OK)
  {
    Error_Handler();
  }
  sMasterConfig.MasterOutputTrigger = TIM_TRGO_RESET;
  sMasterConfig.MasterSlaveMode = TIM_MASTERSLAVEMODE_DISABLE;
  if (HAL_TIMEx_MasterConfigSynchronization(&htim2, &sMasterConfig) != HAL_OK)
  {
    Error_Handler();
  }

}

static void MX_TIM3_Init(void)
{

  TIM_ClockConfigTypeDef sClockSourceConfig = {0};
  TIM_MasterConfigTypeDef sMasterConfig = {0};

  htim3.Instance = TIM3;
  htim3.Init.Prescaler = 500-1;
  htim3.Init.CounterMode = TIM_COUNTERMODE_UP;
  htim3.Init.Period = 400-1;
  htim3.Init.ClockDivision = TIM_CLOCKDIVISION_DIV4;
  htim3.Init.AutoReloadPreload = TIM_AUTORELOAD_PRELOAD_DISABLE;
  if (HAL_TIM_Base_Init(&htim3) != HAL_OK)
  {
    Error_Handler();
  }
  sClockSourceConfig.ClockSource = TIM_CLOCKSOURCE_INTERNAL;
  if (HAL_TIM_ConfigClockSource(&htim3, &sClockSourceConfig) != HAL_OK)
  {
    Error_Handler();
  }
  sMasterConfig.MasterOutputTrigger = TIM_TRGO_RESET;
  sMasterConfig.MasterSlaveMode = TIM_MASTERSLAVEMODE_DISABLE;
  if (HAL_TIMEx_MasterConfigSynchronization(&htim3, &sMasterConfig) != HAL_OK)
  {
    Error_Handler();
  }

}

static void MX_UART4_Init(void)
{

  huart4.Instance = UART4;
  huart4.Init.BaudRate = 8000000;
  huart4.Init.WordLength = UART_WORDLENGTH_8B;
  huart4.Init.StopBits = UART_STOPBITS_1;
  huart4.Init.Parity = UART_PARITY_NONE;
  huart4.Init.Mode = UART_MODE_TX_RX;
  huart4.Init.HwFlowCtl = UART_HWCONTROL_NONE;
  huart4.Init.OverSampling = UART_OVERSAMPLING_8;
  huart4.Init.OneBitSampling = UART_ONE_BIT_SAMPLE_DISABLE;
  huart4.Init.ClockPrescaler = UART_PRESCALER_DIV1;
  huart4.AdvancedInit.AdvFeatureInit = UART_ADVFEATURE_RXOVERRUNDISABLE_INIT;
  huart4.AdvancedInit.OverrunDisable = UART_ADVFEATURE_OVERRUN_DISABLE;
  if (HAL_UART_Init(&huart4) != HAL_OK)
  {
    Error_Handler();
  }
  if (HAL_UARTEx_SetTxFifoThreshold(&huart4, UART_TXFIFO_THRESHOLD_1_8) != HAL_OK)
  {
    Error_Handler();
  }
  if (HAL_UARTEx_SetRxFifoThreshold(&huart4, UART_RXFIFO_THRESHOLD_1_8) != HAL_OK)
  {
    Error_Handler();
  }
  if (HAL_UARTEx_DisableFifoMode(&huart4) != HAL_OK)
  {
    Error_Handler();
  }
  /* USER CODE BEGIN UART4_Init 2 */
  uart_created_list[3] = &huart4;
  /* USER CODE END UART4_Init 2 */

}

static void MX_UART5_Init(void)
{

  huart5.Instance = UART5;
  huart5.Init.BaudRate = 115200;
  huart5.Init.WordLength = UART_WORDLENGTH_8B;
  huart5.Init.StopBits = UART_STOPBITS_1;
  huart5.Init.Parity = UART_PARITY_NONE;
  huart5.Init.Mode = UART_MODE_TX_RX;
  huart5.Init.HwFlowCtl = UART_HWCONTROL_NONE;
  huart5.Init.OverSampling = UART_OVERSAMPLING_16;
  huart5.Init.OneBitSampling = UART_ONE_BIT_SAMPLE_DISABLE;
  huart5.Init.ClockPrescaler = UART_PRESCALER_DIV1;
  huart5.AdvancedInit.AdvFeatureInit = UART_ADVFEATURE_RXOVERRUNDISABLE_INIT;
  huart5.AdvancedInit.OverrunDisable = UART_ADVFEATURE_OVERRUN_DISABLE;
  if (HAL_UART_Init(&huart5) != HAL_OK)
  {
    Error_Handler();
  }
  if (HAL_UARTEx_SetTxFifoThreshold(&huart5, UART_TXFIFO_THRESHOLD_1_8) != HAL_OK)
  {
    Error_Handler();
  }
  if (HAL_UARTEx_SetRxFifoThreshold(&huart5, UART_RXFIFO_THRESHOLD_1_8) != HAL_OK)
  {
    Error_Handler();
  }
  if (HAL_UARTEx_DisableFifoMode(&huart5) != HAL_OK)
  {
    Error_Handler();
  }
  /* USER CODE BEGIN UART5_Init 2 */
  uart_created_list[4] = &huart5;
  /* USER CODE END UART5_Init 2 */

}

static void MX_USART1_UART_Init(void)
{

  huart1.Instance = USART1;
  huart1.Init.BaudRate = 115200;
  huart1.Init.WordLength = UART_WORDLENGTH_8B;
  huart1.Init.StopBits = UART_STOPBITS_1;
  huart1.Init.Parity = UART_PARITY_NONE;
  huart1.Init.Mode = UART_MODE_TX_RX;
  huart1.Init.HwFlowCtl = UART_HWCONTROL_NONE;
  huart1.Init.OverSampling = UART_OVERSAMPLING_16;
  huart1.Init.OneBitSampling = UART_ONE_BIT_SAMPLE_DISABLE;
  huart1.Init.ClockPrescaler = UART_PRESCALER_DIV1;
  huart1.AdvancedInit.AdvFeatureInit = UART_ADVFEATURE_RXOVERRUNDISABLE_INIT;
  huart1.AdvancedInit.OverrunDisable = UART_ADVFEATURE_OVERRUN_DISABLE;
  if (HAL_UART_Init(&huart1) != HAL_OK)
  {
    Error_Handler();
  }
  if (HAL_UARTEx_SetTxFifoThreshold(&huart1, UART_TXFIFO_THRESHOLD_1_8) != HAL_OK)
  {
    Error_Handler();
  }
  if (HAL_UARTEx_SetRxFifoThreshold(&huart1, UART_RXFIFO_THRESHOLD_1_8) != HAL_OK)
  {
    Error_Handler();
  }
  if (HAL_UARTEx_DisableFifoMode(&huart1) != HAL_OK)
  {
    Error_Handler();
  }
  /* USER CODE BEGIN USART1_Init 2 */
  uart_created_list[0] = &huart1;
  /* USER CODE END USART1_Init 2 */

}

static void MX_USART2_UART_Init(void)
{

  huart2.Instance = USART2;
  huart2.Init.BaudRate = 460800;
  huart2.Init.WordLength = UART_WORDLENGTH_8B;
  huart2.Init.StopBits = UART_STOPBITS_1;
  huart2.Init.Parity = UART_PARITY_NONE;
  huart2.Init.Mode = UART_MODE_TX_RX;
  huart2.Init.HwFlowCtl = UART_HWCONTROL_NONE;
  huart2.Init.OverSampling = UART_OVERSAMPLING_16;
  huart2.Init.OneBitSampling = UART_ONE_BIT_SAMPLE_DISABLE;
  huart2.Init.ClockPrescaler = UART_PRESCALER_DIV1;
  huart2.AdvancedInit.AdvFeatureInit = UART_ADVFEATURE_RXOVERRUNDISABLE_INIT;
  huart2.AdvancedInit.OverrunDisable = UART_ADVFEATURE_OVERRUN_DISABLE;
  if (HAL_UART_Init(&huart2) != HAL_OK)
  {
    Error_Handler();
  }
  if (HAL_UARTEx_SetTxFifoThreshold(&huart2, UART_TXFIFO_THRESHOLD_1_8) != HAL_OK)
  {
    Error_Handler();
  }
  if (HAL_UARTEx_SetRxFifoThreshold(&huart2, UART_RXFIFO_THRESHOLD_1_8) != HAL_OK)
  {
    Error_Handler();
  }
  if (HAL_UARTEx_DisableFifoMode(&huart2) != HAL_OK)
  {
    Error_Handler();
  }
  /* USER CODE BEGIN USART2_Init 2 */
  uart_created_list[1] = &huart2;
  /* USER CODE END USART2_Init 2 */

}

static void MX_USART3_UART_Init(void)
{

  huart3.Instance = USART3;
  huart3.Init.BaudRate = 921600;
  huart3.Init.WordLength = UART_WORDLENGTH_8B;
  huart3.Init.StopBits = UART_STOPBITS_1;
  huart3.Init.Parity = UART_PARITY_NONE;
  huart3.Init.Mode = UART_MODE_TX_RX;
  huart3.Init.HwFlowCtl = UART_HWCONTROL_NONE;
  huart3.Init.OverSampling = UART_OVERSAMPLING_16;
  huart3.Init.OneBitSampling = UART_ONE_BIT_SAMPLE_DISABLE;
  huart3.Init.ClockPrescaler = UART_PRESCALER_DIV1;
  huart3.AdvancedInit.AdvFeatureInit = UART_ADVFEATURE_RXOVERRUNDISABLE_INIT;
  huart3.AdvancedInit.OverrunDisable = UART_ADVFEATURE_OVERRUN_DISABLE;
  if (HAL_UART_Init(&huart3) != HAL_OK)
  {
    Error_Handler();
  }
  if (HAL_UARTEx_SetTxFifoThreshold(&huart3, UART_TXFIFO_THRESHOLD_1_8) != HAL_OK)
  {
    Error_Handler();
  }
  if (HAL_UARTEx_SetRxFifoThreshold(&huart3, UART_RXFIFO_THRESHOLD_1_8) != HAL_OK)
  {
    Error_Handler();
  }
  if (HAL_UARTEx_DisableFifoMode(&huart3) != HAL_OK)
  {
    Error_Handler();
  }
  /* USER CODE BEGIN USART3_Init 2 */
  uart_created_list[2] = &huart3;
  /* USER CODE END USART3_Init 2 */

}

static void MX_USART6_UART_Init(void)
{

  huart6.Instance = USART6;
  huart6.Init.BaudRate = 115200;
  huart6.Init.WordLength = UART_WORDLENGTH_8B;
  huart6.Init.StopBits = UART_STOPBITS_1;
  huart6.Init.Parity = UART_PARITY_NONE;
  huart6.Init.Mode = UART_MODE_TX_RX;
  huart6.Init.HwFlowCtl = UART_HWCONTROL_NONE;
  huart6.Init.OverSampling = UART_OVERSAMPLING_16;
  huart6.Init.OneBitSampling = UART_ONE_BIT_SAMPLE_DISABLE;
  huart6.Init.ClockPrescaler = UART_PRESCALER_DIV1;
  huart6.AdvancedInit.AdvFeatureInit = UART_ADVFEATURE_RXOVERRUNDISABLE_INIT;
  huart6.AdvancedInit.OverrunDisable = UART_ADVFEATURE_OVERRUN_DISABLE;
  if (HAL_UART_Init(&huart6) != HAL_OK)
  {
    Error_Handler();
  }
  if (HAL_UARTEx_SetTxFifoThreshold(&huart6, UART_TXFIFO_THRESHOLD_1_8) != HAL_OK)
  {
    Error_Handler();
  }
  if (HAL_UARTEx_SetRxFifoThreshold(&huart6, UART_RXFIFO_THRESHOLD_1_8) != HAL_OK)
  {
    Error_Handler();
  }
  if (HAL_UARTEx_DisableFifoMode(&huart6) != HAL_OK)
  {
    Error_Handler();
  }
  /* USER CODE BEGIN USART6_Init 2 */
  uart_created_list[5] = &huart6;
  /* USER CODE END USART6_Init 2 */

}

static void MX_DMA_Init(void)
{

  /* DMA controller clock enable */
  __HAL_RCC_DMA1_CLK_ENABLE();
  __HAL_RCC_DMA2_CLK_ENABLE();

  /* DMA interrupt init */
  /* DMA1_Stream0_IRQn interrupt configuration */
  HAL_NVIC_SetPriority(DMA1_Stream0_IRQn, 4, 0);
  HAL_NVIC_EnableIRQ(DMA1_Stream0_IRQn);
  /* DMA1_Stream1_IRQn interrupt configuration */
  HAL_NVIC_SetPriority(DMA1_Stream1_IRQn, 4, 0);
  HAL_NVIC_EnableIRQ(DMA1_Stream1_IRQn);
  /* DMA1_Stream2_IRQn interrupt configuration */
  HAL_NVIC_SetPriority(DMA1_Stream2_IRQn, 4, 0);
  HAL_NVIC_EnableIRQ(DMA1_Stream2_IRQn);
  /* DMA1_Stream3_IRQn interrupt configuration */
  HAL_NVIC_SetPriority(DMA1_Stream3_IRQn, 4, 0);
  HAL_NVIC_EnableIRQ(DMA1_Stream3_IRQn);
  /* DMA1_Stream4_IRQn interrupt configuration */
  HAL_NVIC_SetPriority(DMA1_Stream4_IRQn, 4, 0);
  HAL_NVIC_EnableIRQ(DMA1_Stream4_IRQn);
  /* DMA1_Stream5_IRQn interrupt configuration */
  HAL_NVIC_SetPriority(DMA1_Stream5_IRQn, 4, 0);
  HAL_NVIC_EnableIRQ(DMA1_Stream5_IRQn);
  /* DMA1_Stream6_IRQn interrupt configuration */
  HAL_NVIC_SetPriority(DMA1_Stream6_IRQn, 4, 0);
  HAL_NVIC_EnableIRQ(DMA1_Stream6_IRQn);
  /* DMA1_Stream7_IRQn interrupt configuration */
  HAL_NVIC_SetPriority(DMA1_Stream7_IRQn, 4, 0);
  HAL_NVIC_EnableIRQ(DMA1_Stream7_IRQn);
  /* DMA2_Stream0_IRQn interrupt configuration */
  HAL_NVIC_SetPriority(DMA2_Stream0_IRQn, 4, 0);
  HAL_NVIC_EnableIRQ(DMA2_Stream0_IRQn);
  /* DMA2_Stream1_IRQn interrupt configuration */
  HAL_NVIC_SetPriority(DMA2_Stream1_IRQn, 4, 0);
  HAL_NVIC_EnableIRQ(DMA2_Stream1_IRQn);
  /* DMA2_Stream2_IRQn interrupt configuration */
  HAL_NVIC_SetPriority(DMA2_Stream2_IRQn, 4, 0);
  HAL_NVIC_EnableIRQ(DMA2_Stream2_IRQn);
  /* DMA2_Stream3_IRQn interrupt configuration */
  HAL_NVIC_SetPriority(DMA2_Stream3_IRQn, 4, 0);
  HAL_NVIC_EnableIRQ(DMA2_Stream3_IRQn);
  /* DMA2_Stream4_IRQn interrupt configuration */
  HAL_NVIC_SetPriority(DMA2_Stream4_IRQn, 4, 0);
  HAL_NVIC_EnableIRQ(DMA2_Stream4_IRQn);
  /* DMA2_Stream5_IRQn interrupt configuration */
  HAL_NVIC_SetPriority(DMA2_Stream5_IRQn, 4, 0);
  HAL_NVIC_EnableIRQ(DMA2_Stream5_IRQn);
  /* DMA2_Stream6_IRQn interrupt configuration */
  HAL_NVIC_SetPriority(DMA2_Stream6_IRQn, 4, 0);
  HAL_NVIC_EnableIRQ(DMA2_Stream6_IRQn);
  /* DMA2_Stream7_IRQn interrupt configuration */
  HAL_NVIC_SetPriority(DMA2_Stream7_IRQn, 4, 0);
  HAL_NVIC_EnableIRQ(DMA2_Stream7_IRQn);

}

static void MX_GPIO_Init(void)
{
  GPIO_InitTypeDef GPIO_InitStruct = {0};

  /* GPIO Ports Clock Enable */
  __HAL_RCC_GPIOE_CLK_ENABLE();
  __HAL_RCC_GPIOI_CLK_ENABLE();
  __HAL_RCC_GPIOB_CLK_ENABLE();
  __HAL_RCC_GPIOG_CLK_ENABLE();
  __HAL_RCC_GPIOD_CLK_ENABLE();
  __HAL_RCC_GPIOC_CLK_ENABLE();
  __HAL_RCC_GPIOA_CLK_ENABLE();
  __HAL_RCC_GPIOH_CLK_ENABLE();
  __HAL_RCC_GPIOF_CLK_ENABLE();

  /*Configure GPIO pin Output Level */
  HAL_GPIO_WritePin(PIN_BARO_CS_DATA_N_GPIO_Port, PIN_BARO_CS_DATA_N_Pin, GPIO_PIN_SET);

  /*Configure GPIO pin Output Level */
  HAL_GPIO_WritePin(GPIOI, PIN_GNSS1_RESET__N_Pin|PIN_MAG_CS_N_Pin, GPIO_PIN_SET);

  /*Configure GPIO pin Output Level */
  HAL_GPIO_WritePin(GPIOB, PIN_GNSS1_SAFEBOOT_N_Pin|PIN_GNSS2_RESET_N_Pin|PIN_GNSS2_SAFEBOOT_N_Pin, GPIO_PIN_SET);

  /*Configure GPIO pin Output Level */
  HAL_GPIO_WritePin(GPIOG, PIN_TOV_Pin|PIN_PROG_Pin|PIN_RS717_TERM_RX_Pin|PIN_RS717_SHDN_N_Pin
                          |PIN_RS717_MODE2_Pin|PIN_RS717_MODE1_Pin|PIN_RS717_TERM_TX_Pin|PIN_RS717_SLEWRATE_CTRL_Pin
                          |PIN_RS717_DIR_Pin, GPIO_PIN_RESET);

  /*Configure GPIO pin Output Level */
  HAL_GPIO_WritePin(GPIOG, PIN_PPS_OUT_Pin|PIN_BARO_CS_EE_N_Pin|PIN_RS717_MODE_0_Pin|PIN_USER_LED_Pin, GPIO_PIN_SET);

  /*Configure GPIO pin Output Level */
  HAL_GPIO_WritePin(GPIOI, PIN_GNSS1_EXTINT_Pin|PIN_GNSS2_EXTINT_Pin, GPIO_PIN_RESET);

  /*Configure GPIO pin Output Level */
  HAL_GPIO_WritePin(PIN_IMU_RS422_RE_GPIO_Port, PIN_IMU_RS422_RE_Pin, GPIO_PIN_RESET);

  /*Configure GPIO pin Output Level */
  HAL_GPIO_WritePin(PIN_IMU_RS422_DE_GPIO_Port, PIN_IMU_RS422_DE_Pin, GPIO_PIN_RESET);

  /*Configure GPIO pin : PIN_BARO_CS_DATA_N_Pin */
  GPIO_InitStruct.Pin = PIN_BARO_CS_DATA_N_Pin;
  GPIO_InitStruct.Mode = GPIO_MODE_OUTPUT_PP;
  GPIO_InitStruct.Pull = GPIO_PULLUP;
  GPIO_InitStruct.Speed = GPIO_SPEED_FREQ_LOW;
  HAL_GPIO_Init(PIN_BARO_CS_DATA_N_GPIO_Port, &GPIO_InitStruct);

  /*Configure GPIO pins : PIN_BARO_DRDY_N_Pin PIN_GNSS2_TIMEPULSE_N_Pin */
  GPIO_InitStruct.Pin = PIN_BARO_DRDY_N_Pin|PIN_GNSS2_TIMEPULSE_N_Pin;
  GPIO_InitStruct.Mode = GPIO_MODE_IT_FALLING;
  GPIO_InitStruct.Pull = GPIO_NOPULL;
  HAL_GPIO_Init(GPIOE, &GPIO_InitStruct);

  /*Configure GPIO pins : PIN_GNSS1_RESET__N_Pin PIN_MAG_CS_N_Pin PIN_GNSS1_EXTINT_Pin PIN_GNSS2_EXTINT_Pin */
  GPIO_InitStruct.Pin = PIN_GNSS1_RESET__N_Pin|PIN_MAG_CS_N_Pin|PIN_GNSS1_EXTINT_Pin|PIN_GNSS2_EXTINT_Pin;
  GPIO_InitStruct.Mode = GPIO_MODE_OUTPUT_PP;
  GPIO_InitStruct.Pull = GPIO_NOPULL;
  GPIO_InitStruct.Speed = GPIO_SPEED_FREQ_LOW;
  HAL_GPIO_Init(GPIOI, &GPIO_InitStruct);

  /*Configure GPIO pins : PIN_GNSS1_SAFEBOOT_N_Pin PIN_GNSS2_RESET_N_Pin PIN_GNSS2_SAFEBOOT_N_Pin */
  GPIO_InitStruct.Pin = PIN_GNSS1_SAFEBOOT_N_Pin|PIN_GNSS2_RESET_N_Pin|PIN_GNSS2_SAFEBOOT_N_Pin;
  GPIO_InitStruct.Mode = GPIO_MODE_OUTPUT_PP;
  GPIO_InitStruct.Pull = GPIO_NOPULL;
  GPIO_InitStruct.Speed = GPIO_SPEED_FREQ_LOW;
  HAL_GPIO_Init(GPIOB, &GPIO_InitStruct);

  /*Configure GPIO pins : PIN_TOV_Pin PIN_PPS_OUT_Pin PIN_BARO_CS_EE_N_Pin PIN_PROG_Pin
                           PIN_RS717_MODE_0_Pin PIN_RS717_TERM_RX_Pin PIN_RS717_SHDN_N_Pin PIN_USER_LED_Pin
                           PIN_RS717_MODE2_Pin PIN_RS717_MODE1_Pin PIN_RS717_TERM_TX_Pin PIN_RS717_SLEWRATE_CTRL_Pin
                           PIN_RS717_DIR_Pin */
  GPIO_InitStruct.Pin = PIN_TOV_Pin|PIN_PPS_OUT_Pin|PIN_BARO_CS_EE_N_Pin|PIN_PROG_Pin
                          |PIN_RS717_MODE_0_Pin|PIN_RS717_TERM_RX_Pin|PIN_RS717_SHDN_N_Pin|PIN_USER_LED_Pin
                          |PIN_RS717_MODE2_Pin|PIN_RS717_MODE1_Pin|PIN_RS717_TERM_TX_Pin|PIN_RS717_SLEWRATE_CTRL_Pin
                          |PIN_RS717_DIR_Pin;
  GPIO_InitStruct.Mode = GPIO_MODE_OUTPUT_PP;
  GPIO_InitStruct.Pull = GPIO_NOPULL;
  GPIO_InitStruct.Speed = GPIO_SPEED_FREQ_LOW;
  HAL_GPIO_Init(GPIOG, &GPIO_InitStruct);

  /*Configure GPIO pin : PIN_GNSS1_TX_READY_Pin */
  GPIO_InitStruct.Pin = PIN_GNSS1_TX_READY_Pin;
  GPIO_InitStruct.Mode = GPIO_MODE_INPUT;
  GPIO_InitStruct.Pull = GPIO_NOPULL;
  HAL_GPIO_Init(PIN_GNSS1_TX_READY_GPIO_Port, &GPIO_InitStruct);

  /*Configure GPIO pin : PIN_MAG_DRDY_Pin */
  GPIO_InitStruct.Pin = PIN_MAG_DRDY_Pin;
  GPIO_InitStruct.Mode = GPIO_MODE_IT_RISING;
  GPIO_InitStruct.Pull = GPIO_NOPULL;
  HAL_GPIO_Init(PIN_MAG_DRDY_GPIO_Port, &GPIO_InitStruct);

  /*Configure GPIO pin : PIN_GNSS2_TX_READY_Pin */
  GPIO_InitStruct.Pin = PIN_GNSS2_TX_READY_Pin;
  GPIO_InitStruct.Mode = GPIO_MODE_INPUT;
  GPIO_InitStruct.Pull = GPIO_NOPULL;
  HAL_GPIO_Init(PIN_GNSS2_TX_READY_GPIO_Port, &GPIO_InitStruct);

  /*Configure GPIO pin : PIN_GNSS1_TIMEPULSE_N_Pin */
  GPIO_InitStruct.Pin = PIN_GNSS1_TIMEPULSE_N_Pin;
  GPIO_InitStruct.Mode = GPIO_MODE_IT_RISING_FALLING;
  GPIO_InitStruct.Pull = GPIO_NOPULL;
  HAL_GPIO_Init(PIN_GNSS1_TIMEPULSE_N_GPIO_Port, &GPIO_InitStruct);

  /*Configure GPIO pin : PIN_IMU_RS422_RE_Pin */
  GPIO_InitStruct.Pin = PIN_IMU_RS422_RE_Pin;
  GPIO_InitStruct.Mode = GPIO_MODE_OUTPUT_PP;
  GPIO_InitStruct.Pull = GPIO_PULLDOWN;
  GPIO_InitStruct.Speed = GPIO_SPEED_FREQ_LOW;
  HAL_GPIO_Init(PIN_IMU_RS422_RE_GPIO_Port, &GPIO_InitStruct);

  /*Configure GPIO pin : PIN_IMU_RS422_DE_Pin */
  GPIO_InitStruct.Pin = PIN_IMU_RS422_DE_Pin;
  GPIO_InitStruct.Mode = GPIO_MODE_OUTPUT_PP;
  GPIO_InitStruct.Pull = GPIO_PULLDOWN;
  GPIO_InitStruct.Speed = GPIO_SPEED_FREQ_LOW;
  HAL_GPIO_Init(PIN_IMU_RS422_DE_GPIO_Port, &GPIO_InitStruct);

  /*Configure GPIO pin : PIN_SAY_MY_NAME_Pin */
  GPIO_InitStruct.Pin = PIN_SAY_MY_NAME_Pin;
  GPIO_InitStruct.Mode = GPIO_MODE_INPUT;
  GPIO_InitStruct.Pull = GPIO_PULLDOWN;
  HAL_GPIO_Init(PIN_SAY_MY_NAME_GPIO_Port, &GPIO_InitStruct);

  /* EXTI interrupt init*/
  HAL_NVIC_SetPriority(PIN_GNSS2_TIMEPULSE_N_EXTI_IRQn, 2, 0);
  HAL_NVIC_EnableIRQ(PIN_GNSS2_TIMEPULSE_N_EXTI_IRQn);

  HAL_NVIC_SetPriority(PIN_GNSS1_TIMEPULSE_N_EXTI_IRQn, 0, 0);
  HAL_NVIC_EnableIRQ(PIN_GNSS1_TIMEPULSE_N_EXTI_IRQn);

  HAL_NVIC_SetPriority(PIN_BARO_DRDY_N_EXTI_IRQn, 4, 0);
  HAL_NVIC_EnableIRQ(PIN_BARO_DRDY_N_EXTI_IRQn);

  HAL_NVIC_SetPriority(PIN_MAG_DRDY_EXTI_IRQn, 4, 0);
  HAL_NVIC_EnableIRQ(PIN_MAG_DRDY_EXTI_IRQn);

}

 /* MPU Configuration */

void MPU_Config(void)
{
  MPU_Region_InitTypeDef MPU_InitStruct = {0};

  /* Disables the MPU */
  HAL_MPU_Disable();

  /** Initializes and configures the Region and the memory to be protected
  */
  MPU_InitStruct.Enable = MPU_REGION_ENABLE;
  MPU_InitStruct.Number = MPU_REGION_NUMBER0;
  MPU_InitStruct.BaseAddress = 0x24078000;
  MPU_InitStruct.Size = MPU_REGION_SIZE_32KB;
  MPU_InitStruct.SubRegionDisable = 0x0;
  MPU_InitStruct.TypeExtField = MPU_TEX_LEVEL0;
  MPU_InitStruct.AccessPermission = MPU_REGION_FULL_ACCESS;
  MPU_InitStruct.DisableExec = MPU_INSTRUCTION_ACCESS_ENABLE;
  MPU_InitStruct.IsShareable = MPU_ACCESS_SHAREABLE;
  MPU_InitStruct.IsCacheable = MPU_ACCESS_NOT_CACHEABLE;
  MPU_InitStruct.IsBufferable = MPU_ACCESS_BUFFERABLE;

  HAL_MPU_ConfigRegion(&MPU_InitStruct);
  /* Enables the MPU */
  HAL_MPU_Enable(MPU_PRIVILEGED_DEFAULT);

}

void HAL_TIM_PeriodElapsedCallback(TIM_HandleTypeDef *htim)
{
  if (htim->Instance == TIM6)
  {
    HAL_IncTick();
  }
}

void Error_Handler(void)
{
  __disable_irq();
  while (1)
  {
  }
}
